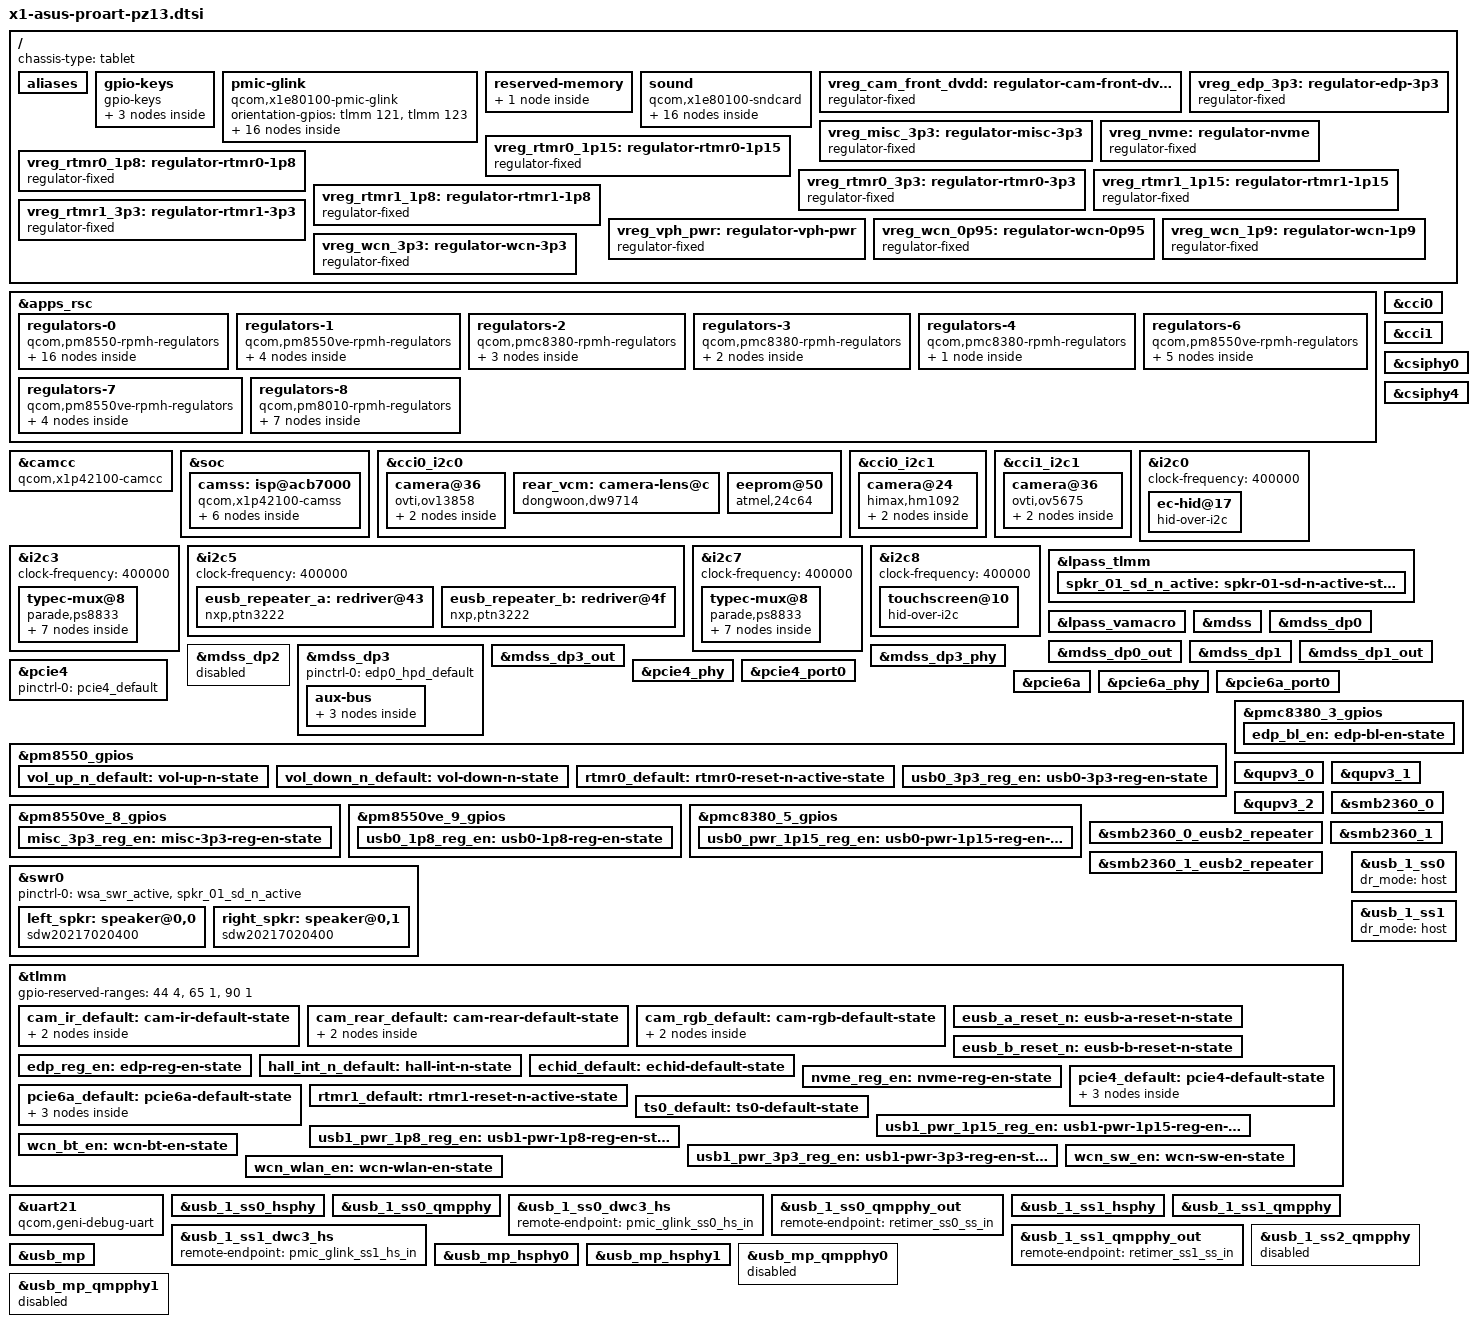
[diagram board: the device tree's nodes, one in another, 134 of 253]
// SPDX-License-Identifier: BSD-3-Clause
/*
 * Copyright (c) 2025 Qualcomm Innovation Center, Inc. All rights reserved.
 * Copyright (c) 2025 Aleksandrs Vinarskis <alex.vinarskis@gmail.com>
 * Copyright (c) 2026 Alex Grucza
 *
 * ASUS ProArt PZ13 (HT5306QA), Snapdragon X Plus X1P-42-100.
 * Derived from x1-asus-zenbook-a14.dtsi; bus assignments, interrupts and
 * supplies verified against the PZ13 ACPI DSDT and by probing. Remaining
 * open points carry a PZ13-TODO marker.
 */

#include <dt-bindings/gpio/gpio.h>
#include <dt-bindings/input/gpio-keys.h>
#include <dt-bindings/input/input.h>
#include <dt-bindings/phy/phy.h>
#include <dt-bindings/pinctrl/qcom,pmic-gpio.h>
#include <dt-bindings/regulator/qcom,rpmh-regulator.h>

#include "hamoa-pmics.dtsi"

/ {
	chassis-type = "tablet";

	aliases {
		serial0 = &uart21;
		serial1 = &uart14;
	};

	gpio-keys {
		compatible = "gpio-keys";

		pinctrl-0 = <&hall_int_n_default>, <&vol_up_n_default>, <&vol_down_n_default>;
		pinctrl-names = "default";

		switch-lid {
			label = "lid";
			gpios = <&tlmm 92 GPIO_ACTIVE_LOW>;
			linux,input-type = <EV_SW>;
			linux,code = <SW_LID>;
			wakeup-source;
			wakeup-event-action = <EV_ACT_DEASSERTED>;
		};

		/*
		 * ACPI \_SB.BTNS (ACPI0011): Volume Increment / Decrement on
		 * PMIC GPIO pins 0xd5 / 0xd7 of \_SB.PM01; pm8550 GPIO 6 and 8
		 * are the two lines the firmware leaves as inputs, as on the
		 * CRD (volume up on GPIO 6).
		 */
		key-vol-up {
			label = "volume_up";
			gpios = <&pm8550_gpios 6 GPIO_ACTIVE_LOW>;
			linux,code = <KEY_VOLUMEUP>;
			debounce-interval = <15>;
			linux,can-disable;
			wakeup-source;
		};

		key-vol-down {
			label = "volume_down";
			gpios = <&pm8550_gpios 8 GPIO_ACTIVE_LOW>;
			linux,code = <KEY_VOLUMEDOWN>;
			debounce-interval = <15>;
			linux,can-disable;
			wakeup-source;
		};
	};

	pmic-glink {
		compatible = "qcom,x1e80100-pmic-glink", "qcom,pmic-glink";
		orientation-gpios = <&tlmm 121 GPIO_ACTIVE_HIGH>,
				    <&tlmm 123 GPIO_ACTIVE_HIGH>;
		#address-cells = <1>;
		#size-cells = <0>;

		/* Left-side display-adjacent port */
		connector@0 {
			compatible = "usb-c-connector";
			reg = <0>;
			power-role = "dual";
			data-role = "dual";

			ports {
				#address-cells = <1>;
				#size-cells = <0>;

				port@0 {
					reg = <0>;

					pmic_glink_ss0_hs_in: endpoint {
						remote-endpoint = <&usb_1_ss0_dwc3_hs>;
					};
				};

				port@1 {
					reg = <1>;

					pmic_glink_ss0_ss_in: endpoint {
						remote-endpoint = <&retimer_ss0_ss_out>;
					};
				};

				port@2 {
					reg = <2>;

					pmic_glink_ss0_con_sbu_in: endpoint {
						remote-endpoint = <&retimer_ss0_con_sbu_out>;
					};
				};
			};
		};

		/* Left-side user-adjacent port */
		connector@1 {
			compatible = "usb-c-connector";
			reg = <1>;
			power-role = "dual";
			data-role = "dual";

			ports {
				#address-cells = <1>;
				#size-cells = <0>;

				port@0 {
					reg = <0>;

					pmic_glink_ss1_hs_in: endpoint {
						remote-endpoint = <&usb_1_ss1_dwc3_hs>;
					};
				};

				port@1 {
					reg = <1>;

					pmic_glink_ss1_ss_in: endpoint {
						remote-endpoint = <&retimer_ss1_ss_out>;
					};
				};

				port@2 {
					reg = <2>;

					pmic_glink_ss1_con_sbu_in: endpoint {
						remote-endpoint = <&retimer_ss1_con_sbu_out>;
					};
				};
			};
		};
	};

	reserved-memory {
		linux,cma {
			compatible = "shared-dma-pool";
			size = <0x0 0x8000000>;
			reusable;
			linux,cma-default;
		};
	};

	/*
	 * Audio, from the Windows audio driver INF (qcaudminiportCRD_Extension):
	 * stereo speakers on the Qualcomm smart-amp path (two WSA8845 on swr0,
	 * enumerated as sdw:1:0:0217:0204:00:{0,1}), a DMIC array on the VA
	 * macro, no headset jack and therefore no WCD codec (swr1/swr2 stay
	 * disabled; swr2 floods "SWR CMD error" interrupts if enabled).
	 * DisplayPort audio over the two USB-C ports as on the Zenbook A14.
	 */
	sound {
		compatible = "qcom,x1e80100-sndcard";
		model = "X1P42100-ASUS-ProArt-PZ13";
		/*
		 * No WCD codec here, so no "VA MIC BIASn" widgets: the DMICs are
		 * powered by the VA macro's vdd-micb-supply, which only gets
		 * enabled when routed to the DMIC inputs.
		 */
		audio-routing = "SpkrLeft IN", "WSA WSA_SPK1 OUT",
				"SpkrRight IN", "WSA WSA_SPK2 OUT",
				"VA DMIC0", "vdd-micb",
				"VA DMIC1", "vdd-micb",
				"VA DMIC2", "vdd-micb",
				"VA DMIC3", "vdd-micb";

		displayport-0-dai-link {
			link-name = "DisplayPort0 Playback";

			codec {
				sound-dai = <&mdss_dp0>;
			};

			cpu {
				sound-dai = <&q6apmbedai DISPLAY_PORT_RX_0>;
			};

			platform {
				sound-dai = <&q6apm>;
			};
		};

		displayport-1-dai-link {
			link-name = "DisplayPort1 Playback";

			codec {
				sound-dai = <&mdss_dp1>;
			};

			cpu {
				sound-dai = <&q6apmbedai DISPLAY_PORT_RX_1>;
			};

			platform {
				sound-dai = <&q6apm>;
			};
		};

		va-dai-link {
			link-name = "VA Capture";

			codec {
				sound-dai = <&lpass_vamacro 0>;
			};

			cpu {
				sound-dai = <&q6apmbedai VA_CODEC_DMA_TX_0>;
			};

			platform {
				sound-dai = <&q6apm>;
			};
		};

		wsa-dai-link {
			link-name = "WSA Playback";

			codec {
				sound-dai = <&left_spkr>, <&right_spkr>,
					    <&swr0 0>, <&lpass_wsamacro 0>;
			};

			cpu {
				sound-dai = <&q6apmbedai WSA_CODEC_DMA_RX_0>;
			};

			platform {
				sound-dai = <&q6apm>;
			};
		};
	};

	/*
	 * Front camera DVDD: the OV5675 module has no external 1.2 V rail in the
	 * Windows power sequence (notes/cameras.md), the sensor streams with AVDD and
	 * DOVDD alone, so the driver's required dvdd-supply is a dummy. (The TLMM 6
	 * toggle in that sequence is the eUSB2 repeater reset of usb_mp, not a camera
	 * supply.)
	 */
	vreg_cam_front_dvdd: regulator-cam-front-dvdd {
		compatible = "regulator-fixed";
		regulator-name = "vreg_cam_front_dvdd";
		regulator-min-microvolt = <1200000>;
		regulator-max-microvolt = <1200000>;
	};

	vreg_edp_3p3: regulator-edp-3p3 {
		compatible = "regulator-fixed";

		regulator-name = "VREG_EDP_3P3";
		regulator-min-microvolt = <3300000>;
		regulator-max-microvolt = <3300000>;

		gpio = <&tlmm 70 GPIO_ACTIVE_HIGH>;
		enable-active-high;

		pinctrl-0 = <&edp_reg_en>;
		pinctrl-names = "default";

		regulator-boot-on;
	};

	/*
	 * PZ13-TODO: inherited from the Zenbook A14, where it is boot-on with no
	 * DT consumer. Not referenced by the PZ13 PEP tables we have looked at;
	 * what pm8550ve_8 GPIO 6 switches on this board is unknown.
	 */
	vreg_misc_3p3: regulator-misc-3p3 {
		compatible = "regulator-fixed";

		regulator-name = "VREG_MISC_3P3";
		regulator-min-microvolt = <3300000>;
		regulator-max-microvolt = <3300000>;

		gpio = <&pm8550ve_8_gpios 6 GPIO_ACTIVE_HIGH>;
		enable-active-high;

		pinctrl-0 = <&misc_3p3_reg_en>;
		pinctrl-names = "default";

		regulator-boot-on;
		regulator-always-on;
	};

	vreg_nvme: regulator-nvme {
		compatible = "regulator-fixed";

		regulator-name = "VREG_NVME_3P3";
		regulator-min-microvolt = <3300000>;
		regulator-max-microvolt = <3300000>;

		gpio = <&tlmm 18 GPIO_ACTIVE_HIGH>;
		enable-active-high;

		pinctrl-0 = <&nvme_reg_en>;
		pinctrl-names = "default";

		regulator-boot-on;
	};

	vreg_rtmr0_1p15: regulator-rtmr0-1p15 {
		compatible = "regulator-fixed";

		regulator-name = "VREG_RTMR0_1P15";
		regulator-min-microvolt = <1150000>;
		regulator-max-microvolt = <1150000>;

		gpio = <&pmc8380_5_gpios 8 GPIO_ACTIVE_HIGH>;
		enable-active-high;

		pinctrl-0 = <&usb0_pwr_1p15_reg_en>;
		pinctrl-names = "default";

		regulator-boot-on;
	};

	vreg_rtmr0_1p8: regulator-rtmr0-1p8 {
		compatible = "regulator-fixed";

		regulator-name = "VREG_RTMR0_1P8";
		regulator-min-microvolt = <1800000>;
		regulator-max-microvolt = <1800000>;

		gpio = <&pm8550ve_9_gpios 8 GPIO_ACTIVE_HIGH>;
		enable-active-high;

		pinctrl-0 = <&usb0_1p8_reg_en>;
		pinctrl-names = "default";

		regulator-boot-on;
	};

	vreg_rtmr0_3p3: regulator-rtmr0-3p3 {
		compatible = "regulator-fixed";

		regulator-name = "VREG_RTMR0_3P3";
		regulator-min-microvolt = <3300000>;
		regulator-max-microvolt = <3300000>;

		gpio = <&pm8550_gpios 11 GPIO_ACTIVE_HIGH>;
		enable-active-high;

		pinctrl-0 = <&usb0_3p3_reg_en>;
		pinctrl-names = "default";

		regulator-boot-on;
	};

	vreg_rtmr1_1p15: regulator-rtmr1-1p15 {
		compatible = "regulator-fixed";

		regulator-name = "VREG_RTMR1_1P15";
		regulator-min-microvolt = <1150000>;
		regulator-max-microvolt = <1150000>;

		gpio = <&tlmm 188 GPIO_ACTIVE_HIGH>;
		enable-active-high;

		pinctrl-0 = <&usb1_pwr_1p15_reg_en>;
		pinctrl-names = "default";

		regulator-boot-on;
	};

	vreg_rtmr1_1p8: regulator-rtmr1-1p8 {
		compatible = "regulator-fixed";

		regulator-name = "VREG_RTMR1_1P8";
		regulator-min-microvolt = <1800000>;
		regulator-max-microvolt = <1800000>;

		gpio = <&tlmm 175 GPIO_ACTIVE_HIGH>;
		enable-active-high;

		pinctrl-0 = <&usb1_pwr_1p8_reg_en>;
		pinctrl-names = "default";

		regulator-boot-on;
	};

	vreg_rtmr1_3p3: regulator-rtmr1-3p3 {
		compatible = "regulator-fixed";

		regulator-name = "VREG_RTMR1_3P3";
		regulator-min-microvolt = <3300000>;
		regulator-max-microvolt = <3300000>;

		gpio = <&tlmm 186 GPIO_ACTIVE_HIGH>;
		enable-active-high;

		pinctrl-0 = <&usb1_pwr_3p3_reg_en>;
		pinctrl-names = "default";

		regulator-boot-on;
	};

	vreg_vph_pwr: regulator-vph-pwr {
		compatible = "regulator-fixed";

		regulator-name = "vph_pwr";
		regulator-min-microvolt = <3700000>;
		regulator-max-microvolt = <3700000>;

		regulator-always-on;
		regulator-boot-on;
	};

	vreg_wcn_0p95: regulator-wcn-0p95 {
		compatible = "regulator-fixed";

		regulator-name = "VREG_WCN_0P95";
		regulator-min-microvolt = <950000>;
		regulator-max-microvolt = <950000>;

		vin-supply = <&vreg_wcn_3p3>;
	};

	vreg_wcn_1p9: regulator-wcn-1p9 {
		compatible = "regulator-fixed";

		regulator-name = "VREG_WCN_1P9";
		regulator-min-microvolt = <1900000>;
		regulator-max-microvolt = <1900000>;

		vin-supply = <&vreg_wcn_3p3>;
	};

	vreg_wcn_3p3: regulator-wcn-3p3 {
		compatible = "regulator-fixed";

		regulator-name = "VREG_WCN_3P3";
		regulator-min-microvolt = <3300000>;
		regulator-max-microvolt = <3300000>;

		gpio = <&tlmm 214 GPIO_ACTIVE_HIGH>;
		enable-active-high;

		pinctrl-0 = <&wcn_sw_en>;
		pinctrl-names = "default";

		regulator-boot-on;
	};
};

&apps_rsc {
	regulators-0 {
		compatible = "qcom,pm8550-rpmh-regulators";
		qcom,pmic-id = "b";

		vdd-bob1-supply = <&vreg_vph_pwr>;
		vdd-bob2-supply = <&vreg_vph_pwr>;
		vdd-l1-l4-l10-supply = <&vreg_s4c_1p8>;
		vdd-l2-l13-l14-supply = <&vreg_bob1>;
		vdd-l5-l16-supply = <&vreg_bob1>;
		vdd-l6-l7-supply = <&vreg_bob2>;
		vdd-l8-l9-supply = <&vreg_bob1>;
		vdd-l12-supply = <&vreg_s5j_1p2>;
		vdd-l15-supply = <&vreg_s4c_1p8>;
		vdd-l17-supply = <&vreg_bob2>;

		vreg_bob1: bob1 {
			regulator-name = "vreg_bob1";
			regulator-min-microvolt = <3008000>;
			regulator-max-microvolt = <3960000>;
			regulator-initial-mode = <RPMH_REGULATOR_MODE_HPM>;
		};

		vreg_bob2: bob2 {
			regulator-name = "vreg_bob2";
			regulator-min-microvolt = <2504000>;
			regulator-max-microvolt = <3008000>;
			regulator-initial-mode = <RPMH_REGULATOR_MODE_HPM>;
		};

		vreg_l1b_1p8: ldo1 {
			regulator-name = "vreg_l1b_1p8";
			regulator-min-microvolt = <1800000>;
			regulator-max-microvolt = <1800000>;
			regulator-initial-mode = <RPMH_REGULATOR_MODE_HPM>;
		};

		vreg_l2b_3p0: ldo2 {
			regulator-name = "vreg_l2b_3p0";
			regulator-min-microvolt = <3072000>;
			regulator-max-microvolt = <3072000>;
			regulator-initial-mode = <RPMH_REGULATOR_MODE_HPM>;
		};

		vreg_l4b_1p8: ldo4 {
			regulator-name = "vreg_l4b_1p8";
			regulator-min-microvolt = <1800000>;
			regulator-max-microvolt = <1800000>;
			regulator-initial-mode = <RPMH_REGULATOR_MODE_HPM>;
		};

		vreg_l5b_3p0: ldo5 {
			regulator-name = "vreg_l5b_3p0";
			regulator-min-microvolt = <3000000>;
			regulator-max-microvolt = <3000000>;
			regulator-initial-mode = <RPMH_REGULATOR_MODE_HPM>;
		};

		vreg_l7b_2p8: ldo7 {
			regulator-name = "vreg_l7b_2p8";
			regulator-min-microvolt = <2800000>;
			regulator-max-microvolt = <2800000>;
			regulator-initial-mode = <RPMH_REGULATOR_MODE_HPM>;
		};

		vreg_l6b_1p8: ldo6 {
			regulator-name = "vreg_l6b_1p8";
			regulator-min-microvolt = <1800000>;
			regulator-max-microvolt = <2960000>;
			regulator-initial-mode = <RPMH_REGULATOR_MODE_HPM>;
		};

		vreg_l8b_3p0: ldo8 {
			regulator-name = "vreg_l8b_3p0";
			regulator-min-microvolt = <3072000>;
			regulator-max-microvolt = <3072000>;
			regulator-initial-mode = <RPMH_REGULATOR_MODE_HPM>;
		};

		vreg_l9b_2p9: ldo9 {
			regulator-name = "vreg_l9b_2p9";
			regulator-min-microvolt = <2960000>;
			regulator-max-microvolt = <2960000>;
			regulator-initial-mode = <RPMH_REGULATOR_MODE_HPM>;
		};

		vreg_l10b_1p8: ldo10 {
			regulator-name = "vreg_l10b_1p8";
			regulator-min-microvolt = <1800000>;
			regulator-max-microvolt = <1800000>;
			regulator-initial-mode = <RPMH_REGULATOR_MODE_HPM>;
		};

		vreg_l12b_1p2: ldo12 {
			regulator-name = "vreg_l12b_1p2";
			regulator-min-microvolt = <1200000>;
			regulator-max-microvolt = <1200000>;
			regulator-initial-mode = <RPMH_REGULATOR_MODE_HPM>;
			regulator-always-on;
		};

		vreg_l13b_3p0: ldo13 {
			regulator-name = "vreg_l13b_3p0";
			regulator-min-microvolt = <3072000>;
			regulator-max-microvolt = <3072000>;
			regulator-initial-mode = <RPMH_REGULATOR_MODE_HPM>;
		};

		vreg_l14b_3p0: ldo14 {
			regulator-name = "vreg_l14b_3p0";
			regulator-min-microvolt = <3072000>;
			regulator-max-microvolt = <3072000>;
			regulator-initial-mode = <RPMH_REGULATOR_MODE_HPM>;
		};

		vreg_l15b_1p8: ldo15 {
			regulator-name = "vreg_l15b_1p8";
			regulator-min-microvolt = <1800000>;
			regulator-max-microvolt = <1800000>;
			regulator-initial-mode = <RPMH_REGULATOR_MODE_HPM>;
			regulator-always-on;
		};

		vreg_l17b_2p5: ldo17 {
			regulator-name = "vreg_l17b_2p5";
			regulator-min-microvolt = <2504000>;
			regulator-max-microvolt = <2504000>;
			regulator-initial-mode = <RPMH_REGULATOR_MODE_HPM>;
		};
	};

	regulators-1 {
		compatible = "qcom,pm8550ve-rpmh-regulators";
		qcom,pmic-id = "c";

		vdd-l1-supply = <&vreg_s5j_1p2>;
		vdd-l2-supply = <&vreg_s1f_0p7>;
		vdd-l3-supply = <&vreg_s1f_0p7>;
		vdd-s4-supply = <&vreg_vph_pwr>;

		vreg_s4c_1p8: smps4 {
			regulator-name = "vreg_s4c_1p8";
			regulator-min-microvolt = <1856000>;
			regulator-max-microvolt = <2000000>;
			regulator-initial-mode = <RPMH_REGULATOR_MODE_HPM>;
		};

		vreg_l1c_1p2: ldo1 {
			regulator-name = "vreg_l1c_1p2";
			regulator-min-microvolt = <1200000>;
			regulator-max-microvolt = <1200000>;
			regulator-initial-mode = <RPMH_REGULATOR_MODE_HPM>;
		};

		vreg_l2c_0p8: ldo2 {
			regulator-name = "vreg_l2c_0p8";
			regulator-min-microvolt = <880000>;
			regulator-max-microvolt = <880000>;
			regulator-initial-mode = <RPMH_REGULATOR_MODE_HPM>;
		};

		vreg_l3c_0p9: ldo3 {
			regulator-name = "vreg_l3c_0p9";
			regulator-min-microvolt = <912000>;
			regulator-max-microvolt = <912000>;
			regulator-initial-mode = <RPMH_REGULATOR_MODE_HPM>;
		};
	};

	regulators-2 {
		compatible = "qcom,pmc8380-rpmh-regulators";
		qcom,pmic-id = "d";

		vdd-l1-supply = <&vreg_s1f_0p7>;
		vdd-l2-supply = <&vreg_s1f_0p7>;
		vdd-l3-supply = <&vreg_s4c_1p8>;
		vdd-s1-supply = <&vreg_vph_pwr>;

		vreg_l1d_0p8: ldo1 {
			regulator-name = "vreg_l1d_0p8";
			regulator-min-microvolt = <880000>;
			regulator-max-microvolt = <880000>;
			regulator-initial-mode = <RPMH_REGULATOR_MODE_HPM>;
		};

		vreg_l2d_0p9: ldo2 {
			regulator-name = "vreg_l2d_0p9";
			regulator-min-microvolt = <912000>;
			regulator-max-microvolt = <912000>;
			regulator-initial-mode = <RPMH_REGULATOR_MODE_HPM>;
		};

		vreg_l3d_1p8: ldo3 {
			regulator-name = "vreg_l3d_1p8";
			regulator-min-microvolt = <1800000>;
			regulator-max-microvolt = <1800000>;
			regulator-initial-mode = <RPMH_REGULATOR_MODE_HPM>;
		};
	};

	regulators-3 {
		compatible = "qcom,pmc8380-rpmh-regulators";
		qcom,pmic-id = "e";

		vdd-l2-supply = <&vreg_s1f_0p7>;
		vdd-l3-supply = <&vreg_s5j_1p2>;

		vreg_l2e_0p8: ldo2 {
			regulator-name = "vreg_l2e_0p8";
			regulator-min-microvolt = <880000>;
			regulator-max-microvolt = <880000>;
			regulator-initial-mode = <RPMH_REGULATOR_MODE_HPM>;
		};

		vreg_l3e_1p2: ldo3 {
			regulator-name = "vreg_l3e_1p2";
			regulator-min-microvolt = <1200000>;
			regulator-max-microvolt = <1200000>;
			regulator-initial-mode = <RPMH_REGULATOR_MODE_HPM>;
		};
	};

	regulators-4 {
		compatible = "qcom,pmc8380-rpmh-regulators";
		qcom,pmic-id = "f";

		vdd-l1-supply = <&vreg_s5j_1p2>;
		vdd-l2-supply = <&vreg_s5j_1p2>;
		vdd-l3-supply = <&vreg_s5j_1p2>;
		vdd-s1-supply = <&vreg_vph_pwr>;

		vreg_s1f_0p7: smps1 {
			regulator-name = "vreg_s1f_0p7";
			regulator-min-microvolt = <700000>;
			regulator-max-microvolt = <1100000>;
			regulator-initial-mode = <RPMH_REGULATOR_MODE_HPM>;
		};
	};

	regulators-6 {
		compatible = "qcom,pm8550ve-rpmh-regulators";
		qcom,pmic-id = "i";

		vdd-l1-supply = <&vreg_s4c_1p8>;
		vdd-l2-supply = <&vreg_s5j_1p2>;
		vdd-l3-supply = <&vreg_s1f_0p7>;
		vdd-s1-supply = <&vreg_vph_pwr>;
		vdd-s2-supply = <&vreg_vph_pwr>;

		vreg_s1i_0p9: smps1 {
			regulator-name = "vreg_s1i_0p9";
			regulator-min-microvolt = <900000>;
			regulator-max-microvolt = <920000>;
			regulator-initial-mode = <RPMH_REGULATOR_MODE_HPM>;
		};

		vreg_s2i_1p0: smps2 {
			regulator-name = "vreg_s2i_1p0";
			regulator-min-microvolt = <1000000>;
			regulator-max-microvolt = <1100000>;
			regulator-initial-mode = <RPMH_REGULATOR_MODE_HPM>;
		};

		vreg_l1i_1p8: ldo1 {
			regulator-name = "vreg_l1i_1p8";
			regulator-min-microvolt = <1800000>;
			regulator-max-microvolt = <1800000>;
			regulator-initial-mode = <RPMH_REGULATOR_MODE_HPM>;
		};

		vreg_l2i_1p2: ldo2 {
			regulator-name = "vreg_l2i_1p2";
			regulator-min-microvolt = <1200000>;
			regulator-max-microvolt = <1200000>;
			regulator-initial-mode = <RPMH_REGULATOR_MODE_HPM>;
		};

		vreg_l3i_0p8: ldo3 {
			regulator-name = "vreg_l3i_0p8";
			regulator-min-microvolt = <880000>;
			regulator-max-microvolt = <880000>;
			regulator-initial-mode = <RPMH_REGULATOR_MODE_HPM>;
		};
	};

	regulators-7 {
		compatible = "qcom,pm8550ve-rpmh-regulators";
		qcom,pmic-id = "j";

		vdd-l1-supply = <&vreg_s1f_0p7>;
		vdd-l2-supply = <&vreg_s5j_1p2>;
		vdd-l3-supply = <&vreg_s1f_0p7>;
		vdd-s5-supply = <&vreg_vph_pwr>;

		vreg_s5j_1p2: smps5 {
			regulator-name = "vreg_s5j_1p2";
			regulator-min-microvolt = <1256000>;
			regulator-max-microvolt = <1304000>;
			regulator-initial-mode = <RPMH_REGULATOR_MODE_HPM>;
		};

		vreg_l1j_0p9: ldo1 {
			regulator-name = "vreg_l1j_0p9";
			regulator-min-microvolt = <912000>;
			regulator-max-microvolt = <912000>;
			regulator-initial-mode = <RPMH_REGULATOR_MODE_HPM>;
		};

		vreg_l2j_1p2: ldo2 {
			regulator-name = "vreg_l2j_1p2";
			regulator-min-microvolt = <1256000>;
			regulator-max-microvolt = <1256000>;
			regulator-initial-mode = <RPMH_REGULATOR_MODE_HPM>;
		};

		vreg_l3j_0p8: ldo3 {
			regulator-name = "vreg_l3j_0p8";
			regulator-min-microvolt = <880000>;
			regulator-max-microvolt = <880000>;
			regulator-initial-mode = <RPMH_REGULATOR_MODE_HPM>;
			/*
			 * PZ13: supplies the QREF block that generates the
			 * reference clocks for the PCIe/USB QMP PHYs (Windows
			 * votes LDO3_J for every PCIe port). Until the TCSR
			 * clk_ref/QREF series describes this properly, keep
			 * it on so the PHYs never init before it is up.
			 */
			regulator-always-on;
			regulator-boot-on;
		};
	};
	/*
	 * PM8010 (camera PMIC, pmic-id "m"). All seven LDOs exist in cmd-db
	 * (ldom1..ldom7). Voltages from the Windows camera power sequences, supply
	 * parents as on the X1E CRD. l5m (2.8 V) feeds the rear camera's VCM.
	 */
	regulators-8 {
		compatible = "qcom,pm8010-rpmh-regulators";
		qcom,pmic-id = "m";

		vdd-l1-l2-supply = <&vreg_s5j_1p2>;
		vdd-l3-l4-supply = <&vreg_s4c_1p8>;
		vdd-l5-supply = <&vreg_bob1>;
		vdd-l6-supply = <&vreg_s4c_1p8>;
		vdd-l7-supply = <&vreg_bob1>;

		vreg_l1m_1p2: ldo1 {
			regulator-name = "vreg_l1m_1p2";
			regulator-min-microvolt = <1200000>;
			regulator-max-microvolt = <1200000>;
			regulator-initial-mode = <RPMH_REGULATOR_MODE_HPM>;
		};

		vreg_l2m_1p2: ldo2 {
			regulator-name = "vreg_l2m_1p2";
			regulator-min-microvolt = <1200000>;
			regulator-max-microvolt = <1200000>;
			regulator-initial-mode = <RPMH_REGULATOR_MODE_HPM>;
		};

		vreg_l3m_1p8: ldo3 {
			regulator-name = "vreg_l3m_1p8";
			regulator-min-microvolt = <1800000>;
			regulator-max-microvolt = <1808000>;
			regulator-initial-mode = <RPMH_REGULATOR_MODE_HPM>;
		};

		/*
		 * I/O rail of the IR camera (its dovdd-supply). The rear camera's
		 * sensor only answers on cci0_i2c0 while this rail is on as well
		 * (Windows switches it on in the rear camera's sequence too),
		 * presumably the pull-ups of that bus hang on it. Nothing can
		 * request it on behalf of a bus, so keep it on (PZ13-TODO).
		 */
		vreg_l4m_1p8: ldo4 {
			regulator-name = "vreg_l4m_1p8";
			regulator-min-microvolt = <1800000>;
			regulator-max-microvolt = <1808000>;
			regulator-initial-mode = <RPMH_REGULATOR_MODE_HPM>;
			regulator-always-on;
		};

		vreg_l5m_2p8: ldo5 {
			regulator-name = "vreg_l5m_2p8";
			regulator-min-microvolt = <2800000>;
			regulator-max-microvolt = <2800000>;
			regulator-initial-mode = <RPMH_REGULATOR_MODE_HPM>;
		};

		vreg_l6m_1p8: ldo6 {
			regulator-name = "vreg_l6m_1p8";
			regulator-min-microvolt = <1800000>;
			regulator-max-microvolt = <1808000>;
			regulator-initial-mode = <RPMH_REGULATOR_MODE_HPM>;
		};

		vreg_l7m_2p8: ldo7 {
			regulator-name = "vreg_l7m_2p8";
			regulator-min-microvolt = <2800000>;
			regulator-max-microvolt = <2800000>;
			regulator-initial-mode = <RPMH_REGULATOR_MODE_HPM>;
		};
	};

};

/*
 * Cameras. Wiring decoded from the Windows camera package (notes/cameras.md):
 * the PZ13 follows the Qualcomm CRD/QRD reference layout. Front RGB OV5675 on
 * cci1_i2c1 / csiphy4 / MCLK4 works (libcamera). IR HM1092 on
 * cci0_i2c1 / MCLK1 / reset tlmm 111 shares csiphy4 with the RGB sensor in
 * Qualcomm "combo mode": RGB on DL0/DL1 with the clock lane, IR on DL2 with
 * DL3 as its clock lane (module descriptions: isComboMode = 1, laneAssign 2).
 * Streams with the camss/csiphy combo-mode patches in patches/.
 * Rear OV13858 on cci0_i2c0 / csiphy0 (4 lanes) / MCLK0, reset tlmm 109;
 * needs the ov13858 device-tree support patch in patches/; VCM dw9714 @0x0c
 * and module EEPROM 24c64 @0x50 on the same bus.
 * PZ13-TODO: PM8550 IR illuminator (\_SB.FLSH in ACPI).
 */
/*
 * X1P42100 (Purwa) has a smaller CAMSS than the X1E80100 described in
 * hamoa.dtsi: no IFE1, no SFE, CSIPHY0 and CSIPHY4 only. With the X1E
 * description the kernel toggles the non-existent IFE1 GDSC on every suspend
 * and resume ("cam_cc_ife_1_gdsc status stuck"). Redefine the node per the
 * qcom,x1p42100-camss binding (Wenmeng Liu, linux-media, v3; patches/) until purwa.dtsi carries it. Ports: port@0 => csiphy0,
 * port@1 => csiphy4.
 */
&camcc {
	compatible = "qcom,x1p42100-camcc";
};

/*
 * The X1E80100 CAMSS node from hamoa.dtsi is replaced by an X1P42100 one
 * (different unit address, register set and power domains), see below.
 */
/delete-node/ &camss;

&soc {
	camss: isp@acb7000 {
		compatible = "qcom,x1p42100-camss";
		reg = <0 0x0acb7000 0 0x2000>,
		      <0 0x0acb9000 0 0x2000>,
		      <0 0x0acbb000 0 0x2000>,
		      <0 0x0acc6000 0 0x1000>,
		      <0 0x0acca000 0 0x1000>,
		      <0 0x0acb6000 0 0x1000>,
		      <0 0x0acf6000 0 0x1000>,
		      <0 0x0acf7000 0 0x1000>,
		      <0 0x0acf8000 0 0x1000>,
		      <0 0x0ac62000 0 0xf000>,
		      <0 0x0acc7000 0 0x1000>,
		      <0 0x0accb000 0 0x1000>;
		reg-names = "csid0",
			    "csid1",
			    "csid2",
			    "csid_lite0",
			    "csid_lite1",
			    "csid_wrapper",
			    "csitpg0",
			    "csitpg1",
			    "csitpg2",
			    "vfe0",
			    "vfe_lite0",
			    "vfe_lite1";
		clocks = <&camcc CAM_CC_CAMNOC_AXI_RT_CLK>,
			 <&camcc CAM_CC_CPAS_AHB_CLK>,
			 <&camcc CAM_CC_CPAS_FAST_AHB_CLK>,
			 <&camcc CAM_CC_CPAS_IFE_0_CLK>,
			 <&camcc CAM_CC_CPAS_IFE_LITE_CLK>,
			 <&camcc CAM_CC_CSID_CLK>,
			 <&camcc CAM_CC_CSID_CSIPHY_RX_CLK>,
			 <&gcc GCC_CAMERA_HF_AXI_CLK>,
			 <&camcc CAM_CC_IFE_0_CLK>,
			 <&camcc CAM_CC_IFE_0_FAST_AHB_CLK>,
			 <&camcc CAM_CC_IFE_LITE_CLK>,
			 <&camcc CAM_CC_IFE_LITE_AHB_CLK>,
			 <&camcc CAM_CC_IFE_LITE_CPHY_RX_CLK>,
			 <&camcc CAM_CC_IFE_LITE_CSID_CLK>;
		clock-names = "camnoc_rt_axi",
			      "cpas_ahb",
			      "cpas_fast_ahb",
			      "cpas_vfe0",
			      "cpas_vfe_lite",
			      "csid",
			      "csid_csiphy_rx",
			      "gcc_axi_hf",
			      "vfe0",
			      "vfe0_fast_ahb",
			      "vfe_lite",
			      "vfe_lite_ahb",
			      "vfe_lite_cphy_rx",
			      "vfe_lite_csid";
		interrupts = <GIC_SPI 464 IRQ_TYPE_EDGE_RISING>,
			     <GIC_SPI 466 IRQ_TYPE_EDGE_RISING>,
			     <GIC_SPI 431 IRQ_TYPE_EDGE_RISING>,
			     <GIC_SPI 468 IRQ_TYPE_EDGE_RISING>,
			     <GIC_SPI 359 IRQ_TYPE_EDGE_RISING>,
			     <GIC_SPI 465 IRQ_TYPE_EDGE_RISING>,
			     <GIC_SPI 469 IRQ_TYPE_EDGE_RISING>,
			     <GIC_SPI 360 IRQ_TYPE_EDGE_RISING>;
		interrupt-names = "csid0",
				  "csid1",
				  "csid2",
				  "csid_lite0",
				  "csid_lite1",
				  "vfe0",
				  "vfe_lite0",
				  "vfe_lite1";
		interconnects = <&gem_noc MASTER_APPSS_PROC QCOM_ICC_TAG_ACTIVE_ONLY
				 &config_noc SLAVE_CAMERA_CFG QCOM_ICC_TAG_ACTIVE_ONLY>,
				<&mmss_noc MASTER_CAMNOC_HF QCOM_ICC_TAG_ALWAYS
				 &mc_virt SLAVE_EBI1 QCOM_ICC_TAG_ALWAYS>;
		interconnect-names = "ahb",
				     "hf_mnoc";
		iommus = <&apps_smmu 0x800 0x60>,
			 <&apps_smmu 0x820 0x60>;
		phys = <&csiphy0>, <&csiphy4>;
		phy-names = "csiphy0", "csiphy4";
		power-domains = <&camcc CAM_CC_IFE_0_GDSC>,
				<&camcc CAM_CC_TITAN_TOP_GDSC>;
		power-domain-names = "ife0",
				     "top";

		status = "okay";

		ports {
			#address-cells = <1>;
			#size-cells = <0>;

			/* port0 => csiphy0, port1 => csiphy4 */
			port@0 {
				reg = <0>;
				#address-cells = <1>;
				#size-cells = <0>;

				csiphy0_ep: endpoint@0 {
					reg = <0>;
					clock-lanes = <7>;
					data-lanes = <0 1 2 3>;
					remote-endpoint = <&ov13858_ep>;
				};
			};

			port@1 {
				reg = <1>;
				#address-cells = <1>;
				#size-cells = <0>;

				csiphy4_ep: endpoint@4 {
					reg = <4>;
					clock-lanes = <7>;
					data-lanes = <0 1>;
					remote-endpoint = <&ov5675_ep>;
				};

				csiphy4_ir_ep: endpoint@5 {
					reg = <5>;
					clock-lanes = <7>;
					data-lanes = <2>;
					remote-endpoint = <&hm1092_ep>;
				};
			};
		};
	};
};

&cci0 {
	status = "okay";
};

&cci0_i2c0 {
	/* Rear (world-facing) camera; the module straps the sensor to 0x36 */
	camera@36 {
		compatible = "ovti,ov13858";
		reg = <0x36>;

		reset-gpios = <&tlmm 109 GPIO_ACTIVE_LOW>;
		pinctrl-0 = <&cam_rear_default>;
		pinctrl-names = "default";

		/* Windows runs MCLK0 at 24 MHz; the Linux driver requires 19.2 MHz */
		clocks = <&camcc CAM_CC_MCLK0_CLK>;
		assigned-clocks = <&camcc CAM_CC_MCLK0_CLK>;
		assigned-clock-rates = <19200000>;

		orientation = <1>;

		avdd-supply = <&vreg_l7b_2p8>;
		dovdd-supply = <&vreg_l6m_1p8>;
		dvdd-supply = <&vreg_l2m_1p2>;

		lens-focus = <&rear_vcm>;

		port {
			ov13858_ep: endpoint {
				data-lanes = <1 2 3 4>;
				link-frequencies = /bits/ 64 <540000000 270000000>;
				remote-endpoint = <&csiphy0_ep>;
			};
		};
	};

	/* Rear camera focus motor (Windows module data: actuator at 0x18 8-bit) */
	rear_vcm: camera-lens@c {
		compatible = "dongwoon,dw9714";
		reg = <0x0c>;
		vcc-supply = <&vreg_l5m_2p8>;
	};

	/* Rear camera module EEPROM (Windows module data: 0xa0 8-bit, 16-bit addresses) */
	eeprom@50 {
		compatible = "atmel,24c64";
		reg = <0x50>;
		vcc-supply = <&vreg_l6m_1p8>;
		read-only;
	};
};

&cci0_i2c1 {
	/* Front IR camera (Windows Hello) */
	camera@24 {
		compatible = "himax,hm1092";
		reg = <0x24>;

		reset-gpios = <&tlmm 111 GPIO_ACTIVE_LOW>;
		pinctrl-0 = <&cam_ir_default>;
		pinctrl-names = "default";

		clocks = <&camcc CAM_CC_MCLK1_CLK>;
		assigned-clocks = <&camcc CAM_CC_MCLK1_CLK>;
		assigned-clock-rates = <24000000>;

		orientation = <0>;
		rotation = <180>;

		avdd-supply = <&vreg_l7m_2p8>;
		dvdd-supply = <&vreg_l1m_1p2>;
		dovdd-supply = <&vreg_l4m_1p8>;

		port {
			hm1092_ep: endpoint {
				data-lanes = <1>;
				link-frequencies = /bits/ 64 <180000000>;
				remote-endpoint = <&csiphy4_ir_ep>;
			};
		};
	};
};

&cci1 {
	status = "okay";
};

&cci1_i2c1 {
	/* Front (user-facing) camera */
	camera@36 {
		compatible = "ovti,ov5675";
		reg = <0x36>;

		reset-gpios = <&tlmm 237 GPIO_ACTIVE_LOW>;
		pinctrl-0 = <&cam_rgb_default>;
		pinctrl-names = "default";

		/* Windows runs MCLK4 at 24 MHz; the Linux driver requires 19.2 MHz */
		clocks = <&camcc CAM_CC_MCLK4_CLK>;
		assigned-clocks = <&camcc CAM_CC_MCLK4_CLK>;
		assigned-clock-rates = <19200000>;

		orientation = <0>;

		avdd-supply = <&vreg_l5b_3p0>;
		dovdd-supply = <&vreg_l3m_1p8>;
		dvdd-supply = <&vreg_cam_front_dvdd>;

		port {
			ov5675_ep: endpoint {
				data-lanes = <1 2>;
				link-frequencies = /bits/ 64 <450000000>;
				remote-endpoint = <&csiphy4_ep>;
			};
		};
	};
};

&csiphy0 {
	vdda-0p8-supply = <&vreg_l2c_0p8>;
	vdda-1p2-supply = <&vreg_l1c_1p2>;
	phy-type = <PHY_TYPE_DPHY>;

	status = "okay";
};

&csiphy4 {
	vdda-0p8-supply = <&vreg_l2c_0p8>;
	vdda-1p2-supply = <&vreg_l1c_1p2>;
	phy-type = <PHY_TYPE_DPHY>;

	status = "okay";
};

&i2c0 {
	/* ACPI: \_SB.I2C1 = QUP_0_SE_0 @ 0x00b80000 = Linux i2c0, 400 kHz */
	clock-frequency = <400000>;

	status = "okay";

	/*
	 * ACPI: \_SB.ECKB, _HID QTEC0001, _CID PNP0C50, _UID 3, slave 0x17,
	 * HID descriptor register 0x0001, GpioInt edge-low shared.
	 * This is the ASUS EC HID channel (hotkeys, tablet mode), the same
	 * kind of device the Zenbook A14 exposes as hdtl@17 (0B05:4543).
	 * The detachable keyboard cover is a plain USB device (0B05:1B6E)
	 * and needs nothing here.
	 * Interrupt on tlmm 67 (ACPI handle 0x0180 is a PEP handle, not a TLMM
	 * number); the device binds and answers, whether the IRQ fires on
	 * hotkeys is still unverified (PZ13-TODO).
	 */
	ec-hid@17 {
		compatible = "hid-over-i2c";
		reg = <0x17>;

		hid-descr-addr = <0x1>;
		interrupts-extended = <&tlmm 67 IRQ_TYPE_LEVEL_LOW>;

		pinctrl-0 = <&echid_default>;
		pinctrl-names = "default";

		wakeup-source;
	};
};

&i2c3 {
	clock-frequency = <400000>;

	status = "okay";

	/* Left-side display-adjacent port */
	typec-mux@8 {
		compatible = "parade,ps8833", "parade,ps8830";
		reg = <0x08>;

		clocks = <&rpmhcc RPMH_RF_CLK3>;

		vdd-supply = <&vreg_rtmr0_1p15>;
		vdd33-supply = <&vreg_rtmr0_3p3>;
		vdd33-cap-supply = <&vreg_rtmr0_3p3>;
		vddar-supply = <&vreg_rtmr0_1p15>;
		vddat-supply = <&vreg_rtmr0_1p15>;
		vddio-supply = <&vreg_rtmr0_1p8>;

		reset-gpios = <&pm8550_gpios 10 GPIO_ACTIVE_LOW>;

		pinctrl-0 = <&rtmr0_default>;
		pinctrl-names = "default";

		retimer-switch;
		orientation-switch;

		ports {
			#address-cells = <1>;
			#size-cells = <0>;

			port@0 {
				reg = <0>;

				retimer_ss0_ss_out: endpoint {
					remote-endpoint = <&pmic_glink_ss0_ss_in>;
				};
			};

			port@1 {
				reg = <1>;

				retimer_ss0_ss_in: endpoint {
					remote-endpoint = <&usb_1_ss0_qmpphy_out>;
				};
			};

			port@2 {
				reg = <2>;

				retimer_ss0_con_sbu_out: endpoint {
					remote-endpoint = <&pmic_glink_ss0_con_sbu_in>;
				};
			};
		};
	};
};

/*
 * ACPI: \_SB.I2C6 = QUP_0_SE_5 @ 0x00b94000 = Linux i2c5. This is the ASUS EC
 * bus (EC @0x5b, second device @0x76, both answer on i2cdetect). The Zenbook's
 * PTN3222 eUSB repeater @0x4f is not present here (not in ACPI, usb_mp port 1
 * is unconnected on the PZ13).
 * PZ13-TODO: EC driver (protocol documented in README.md).
 */
/*
 * ACPI: \_SB.USB3 (QCOM0D08, the multiport host at 0x0a400000) lists two I2C
 * devices on \_SB.I2C6 (= i2c5) at 0x43 and 0x4f and GpioIo 6 and 184: the two
 * eUSB2 repeaters of usb_mp with their reset lines, as on the other X1 laptops
 * (nxp,ptn3222). They probe. The cover's behaviour across suspend is governed
 * by the missing USB wakeup (see &usb_mp), not by the repeaters. Which repeater
 * serves which port follows the Zenbook A14 (0x4f/tlmm 184 on hsphy1 = cover);
 * PZ13-TODO: confirm.
 */
&i2c5 {
	clock-frequency = <400000>;

	status = "okay";

	eusb_repeater_a: redriver@43 {
		compatible = "nxp,ptn3222";
		reg = <0x43>;
		#phy-cells = <0>;

		vdd3v3-supply = <&vreg_l13b_3p0>;
		vdd1v8-supply = <&vreg_l4b_1p8>;

		reset-gpios = <&tlmm 6 GPIO_ACTIVE_LOW>;

		pinctrl-0 = <&eusb_a_reset_n>;
		pinctrl-names = "default";
	};

	eusb_repeater_b: redriver@4f {
		compatible = "nxp,ptn3222";
		reg = <0x4f>;
		#phy-cells = <0>;

		vdd3v3-supply = <&vreg_l13b_3p0>;
		vdd1v8-supply = <&vreg_l4b_1p8>;

		reset-gpios = <&tlmm 184 GPIO_ACTIVE_LOW>;

		pinctrl-0 = <&eusb_b_reset_n>;
		pinctrl-names = "default";
	};

	/* EC @0x5b and @0x76 (ACPI I2C6); no Linux driver yet */
};

/*
 * ACPI: \_SB.I2C8 = QUP_0_SE_7 @ 0x00b9c000 = Linux i2c7. PS8833 retimer for
 * USB-C port 1 @0x08, same wiring as the Zenbook A14; probes and works.
 */
&i2c7 {
	clock-frequency = <400000>;

	status = "okay";

	/* Left-side user-adjacent port */
	typec-mux@8 {
		compatible = "parade,ps8833", "parade,ps8830";
		reg = <0x08>;

		clocks = <&rpmhcc RPMH_RF_CLK4>;

		vdd-supply = <&vreg_rtmr1_1p15>;
		vdd33-supply = <&vreg_rtmr1_3p3>;
		vdd33-cap-supply = <&vreg_rtmr1_3p3>;
		vddar-supply = <&vreg_rtmr1_1p15>;
		vddat-supply = <&vreg_rtmr1_1p15>;
		vddio-supply = <&vreg_rtmr1_1p8>;

		reset-gpios = <&tlmm 176 GPIO_ACTIVE_LOW>;

		pinctrl-0 = <&rtmr1_default>;
		pinctrl-names = "default";

		retimer-switch;
		orientation-switch;

		ports {
			#address-cells = <1>;
			#size-cells = <0>;

			port@0 {
				reg = <0>;

				retimer_ss1_ss_out: endpoint {
					remote-endpoint = <&pmic_glink_ss1_ss_in>;
				};
			};

			port@1 {
				reg = <1>;

				retimer_ss1_ss_in: endpoint {
					remote-endpoint = <&usb_1_ss1_qmpphy_out>;
				};
			};

			port@2 {
				reg = <2>;

				retimer_ss1_con_sbu_out: endpoint {
					remote-endpoint = <&pmic_glink_ss1_con_sbu_in>;
				};
			};
		};
	};
};

&i2c8 {
	/* ACPI: \_SB.I2C9 = QUP_1_SE_0 @ 0x00a80000 = Linux i2c8, 400 kHz */
	clock-frequency = <400000>;

	status = "okay";

	/*
	 * ACPI: \_SB.TSC1, _HID ELAN9008, _CID PNP0C50, slave 0x10,
	 * HID descriptor register 0x0001, GpioInt level-low shared.
	 * The ACPI GpioInt pin (0x0400) is a Windows PEP handle, not a TLMM
	 * number. Verified on hardware: tlmm 51 counts in /proc/interrupts on
	 * touch; the controller enumerates as ELAN 04F3:430A with multitouch
	 * and a stylus collection (MPP pen).
	 */
	touchscreen@10 {
		compatible = "hid-over-i2c";
		reg = <0x10>;

		hid-descr-addr = <0x1>;
		interrupts-extended = <&tlmm 51 IRQ_TYPE_LEVEL_LOW>;

		pinctrl-0 = <&ts0_default>;
		pinctrl-names = "default";

		wakeup-source;
	};
};

&lpass_tlmm {
	spkr_01_sd_n_active: spkr-01-sd-n-active-state {
		pins = "gpio12";
		function = "gpio";
		drive-strength = <16>;
		bias-disable;
		output-low;
	};
};

&lpass_vamacro {
	pinctrl-0 = <&dmic01_default>, <&dmic23_default>;
	pinctrl-names = "default";

	vdd-micb-supply = <&vreg_l1b_1p8>;
	qcom,dmic-sample-rate = <4800000>;
};

&mdss {
	status = "okay";
};

&mdss_dp0 {
	status = "okay";
};

&mdss_dp0_out {
	link-frequencies = /bits/ 64 <1620000000 2700000000 5400000000 8100000000>;
};

&mdss_dp1 {
	status = "okay";
};

&mdss_dp1_out {
	link-frequencies = /bits/ 64 <1620000000 2700000000 5400000000 8100000000>;
};

/* PZ13: no third USB-C/HDMI port, DP2 unused */
&mdss_dp2 {
	status = "disabled";
};

&mdss_dp3 {
	/delete-property/ #sound-dai-cells;

	pinctrl-0 = <&edp0_hpd_default>;
	pinctrl-names = "default";

	status = "okay";

	aux-bus {
		/*
		 * Samsung ATNA33AA08-0 OLED (EDID SDC 0x41b0). Dedicated driver
		 * with the panel's enable line, as on the Zenbook A14 and the
		 * Vivobook S15; the generic edp-panel driver does not know this
		 * panel and uses conservative timings (2 s before a power-on).
		 */
		panel: panel {
			compatible = "samsung,atna33aa08", "samsung,atna33xc20";
			enable-gpios = <&pmc8380_3_gpios 4 GPIO_ACTIVE_HIGH>;
			power-supply = <&vreg_edp_3p3>;

			pinctrl-0 = <&edp_bl_en>;
			pinctrl-names = "default";

			port {
				edp_panel_in: endpoint {
					remote-endpoint = <&mdss_dp3_out>;
				};
			};
		};
	};
};

&mdss_dp3_out {
	data-lanes = <0 1 2 3>;
	link-frequencies = /bits/ 64 <1620000000 2700000000 5400000000 8100000000>;

	remote-endpoint = <&edp_panel_in>;
};

&mdss_dp3_phy {
	vdda-phy-supply = <&vreg_l3j_0p8>;
	vdda-pll-supply = <&vreg_l2j_1p2>;

	status = "okay";
};

&pcie4 {
	pinctrl-0 = <&pcie4_default>;
	pinctrl-names = "default";

	status = "okay";
};

&pcie4_phy {
	/*
	 * Supplies match the Windows PEP votes (LDO3_I / LDO3_E). The QREF
	 * reference clock block additionally needs vreg_l3j_0p8, kept always-on
	 * above; without it the PHY init times out sporadically on battery.
	 */
	vdda-phy-supply = <&vreg_l3i_0p8>;
	vdda-pll-supply = <&vreg_l3e_1p2>;

	status = "okay";
};

&pcie4_port0 {
	reset-gpios = <&tlmm 146 GPIO_ACTIVE_LOW>;
	wake-gpios = <&tlmm 148 GPIO_ACTIVE_LOW>;
};

&pcie6a {
	vddpe-3v3-supply = <&vreg_nvme>;

	pinctrl-0 = <&pcie6a_default>;
	pinctrl-names = "default";

	status = "okay";
};

&pcie6a_phy {
	vdda-phy-supply = <&vreg_l1d_0p8>;
	vdda-pll-supply = <&vreg_l2j_1p2>;

	status = "okay";
};

&pcie6a_port0 {
	reset-gpios = <&tlmm 152 GPIO_ACTIVE_LOW>;
	wake-gpios = <&tlmm 154 GPIO_ACTIVE_LOW>;
};

&pm8550_gpios {
	vol_up_n_default: vol-up-n-state {
		pins = "gpio6";
		function = "normal";
		power-source = <1>;
		bias-pull-up;
		input-enable;
	};

	vol_down_n_default: vol-down-n-state {
		pins = "gpio8";
		function = "normal";
		power-source = <1>;
		bias-pull-up;
		input-enable;
	};

	rtmr0_default: rtmr0-reset-n-active-state {
		pins = "gpio10";
		function = "normal";
		power-source = <1>;
		bias-disable;
		input-disable;
		output-enable;
	};

	usb0_3p3_reg_en: usb0-3p3-reg-en-state {
		pins = "gpio11";
		function = "normal";
		power-source = <1>;
		bias-disable;
		input-disable;
		output-enable;
	};
};

&pm8550ve_8_gpios {
	misc_3p3_reg_en: misc-3p3-reg-en-state {
		pins = "gpio6";
		function = "normal";
		power-source = <1>;
		bias-disable;
		input-disable;
		output-enable;
		drive-push-pull;
		qcom,drive-strength = <PMIC_GPIO_STRENGTH_LOW>;
	};
};

&pm8550ve_9_gpios {
	usb0_1p8_reg_en: usb0-1p8-reg-en-state {
		pins = "gpio8";
		function = "normal";
		power-source = <1>;
		bias-disable;
		input-disable;
		output-enable;
	};
};

&pmc8380_3_gpios {
	edp_bl_en: edp-bl-en-state {
		pins = "gpio4";
		function = "normal";
		power-source = <1>; /* 1.8 V */
		qcom,drive-strength = <PMIC_GPIO_STRENGTH_MED>;
		bias-pull-down;
		input-disable;
		output-enable;
	};
};

&pmc8380_5_gpios {
	usb0_pwr_1p15_reg_en: usb0-pwr-1p15-reg-en-state {
		pins = "gpio8";
		function = "normal";
		power-source = <1>;
		bias-disable;
		input-disable;
		output-enable;
	};
};

&qupv3_0 {
	status = "okay";
};

&qupv3_1 {
	status = "okay";
};

&qupv3_2 {
	status = "okay";
};

&smb2360_0 {
	status = "okay";
};

&smb2360_0_eusb2_repeater {
	vdd18-supply = <&vreg_l3d_1p8>;
	vdd3-supply = <&vreg_l2b_3p0>;
};

&smb2360_1 {
	status = "okay";
};

&smb2360_1_eusb2_repeater {
	vdd18-supply = <&vreg_l3d_1p8>;
	vdd3-supply = <&vreg_l14b_3p0>;
};

&swr0 {
	status = "okay";

	pinctrl-0 = <&wsa_swr_active>, <&spkr_01_sd_n_active>;
	pinctrl-names = "default";

	/* WSA8845, left speaker */
	left_spkr: speaker@0,0 {
		compatible = "sdw20217020400";
		reg = <0 0>;
		reset-gpios = <&lpass_tlmm 12 GPIO_ACTIVE_LOW>;
		#sound-dai-cells = <0>;
		sound-name-prefix = "SpkrLeft";
		vdd-1p8-supply = <&vreg_l15b_1p8>;
		vdd-io-supply = <&vreg_l12b_1p2>;
		qcom,port-mapping = <1 2 3 7 10 13>;
	};

	/* WSA8845, right speaker */
	right_spkr: speaker@0,1 {
		compatible = "sdw20217020400";
		reg = <0 1>;
		reset-gpios = <&lpass_tlmm 12 GPIO_ACTIVE_LOW>;
		#sound-dai-cells = <0>;
		sound-name-prefix = "SpkrRight";
		vdd-1p8-supply = <&vreg_l15b_1p8>;
		vdd-io-supply = <&vreg_l12b_1p2>;
		qcom,port-mapping = <4 5 6 7 11 13>;
	};
};

&tlmm {
	gpio-reserved-ranges = <44 4>,  /* SPI11, TZ Protected */
			       <65 1>,  /* EC reset (active high), see Abel Vesa's
					  hamoa/purwa EC-reset series */
			       <90 1>;	/* Unknown, TZ Protected */

	cam_ir_default: cam-ir-default-state {
		mclk-pins {
			pins = "gpio97";
			function = "cam_mclk";
			drive-strength = <16>;
			bias-disable;
		};

		reset-n-pins {
			pins = "gpio111";
			function = "gpio";
			drive-strength = <2>;
			bias-disable;
		};
	};

	cam_rear_default: cam-rear-default-state {
		mclk-pins {
			pins = "gpio96";
			function = "cam_mclk";
			drive-strength = <16>;
			bias-disable;
		};

		reset-n-pins {
			pins = "gpio109";
			function = "gpio";
			drive-strength = <2>;
			bias-disable;
		};
	};

	cam_rgb_default: cam-rgb-default-state {
		mclk-pins {
			pins = "gpio100";
			function = "cam_aon";
			drive-strength = <16>;
			bias-disable;
		};

		reset-n-pins {
			pins = "gpio237";
			function = "gpio";
			drive-strength = <2>;
			bias-disable;
		};
	};

	eusb_a_reset_n: eusb-a-reset-n-state {
		pins = "gpio6";
		function = "gpio";
		drive-strength = <2>;
		bias-disable;
	};

	eusb_b_reset_n: eusb-b-reset-n-state {
		pins = "gpio184";
		function = "gpio";
		drive-strength = <2>;
		bias-disable;
	};

	edp_reg_en: edp-reg-en-state {
		pins = "gpio70";
		function = "gpio";
		drive-strength = <16>;
		bias-disable;
	};

	hall_int_n_default: hall-int-n-state {
		pins = "gpio92";
		function = "gpio";
		bias-disable;
	};

	echid_default: echid-default-state {
		pins = "gpio67";
		function = "gpio";
		bias-pull-up;
	};

	nvme_reg_en: nvme-reg-en-state {
		pins = "gpio18";
		function = "gpio";
		drive-strength = <2>;
		bias-disable;
	};

	pcie4_default: pcie4-default-state {
		clkreq-n-pins {
			pins = "gpio147";
			function = "pcie4_clk";
			drive-strength = <2>;
			bias-pull-up;
		};

		perst-n-pins {
			pins = "gpio146";
			function = "gpio";
			drive-strength = <2>;
			bias-disable;
		};

		wake-n-pins {
			pins = "gpio148";
			function = "gpio";
			drive-strength = <2>;
			bias-pull-up;
		};
	};

	pcie6a_default: pcie6a-default-state {
		clkreq-n-pins {
			pins = "gpio153";
			function = "pcie6a_clk";
			drive-strength = <2>;
			bias-pull-up;
		};

		perst-n-pins {
			pins = "gpio152";
			function = "gpio";
			drive-strength = <2>;
			bias-disable;
		};

		wake-n-pins {
			pins = "gpio154";
			function = "gpio";
			drive-strength = <2>;
			bias-pull-up;
		};
	};

	rtmr1_default: rtmr1-reset-n-active-state {
		pins = "gpio176";
		function = "gpio";
		drive-strength = <2>;
		bias-disable;
	};

	ts0_default: ts0-default-state {
		pins = "gpio51";
		function = "gpio";
		bias-pull-up;
	};

	usb1_pwr_1p15_reg_en: usb1-pwr-1p15-reg-en-state {
		pins = "gpio188";
		function = "gpio";
		drive-strength = <2>;
		bias-disable;
	};

	usb1_pwr_1p8_reg_en: usb1-pwr-1p8-reg-en-state {
		pins = "gpio175";
		function = "gpio";
		drive-strength = <2>;
		bias-disable;
	};

	usb1_pwr_3p3_reg_en: usb1-pwr-3p3-reg-en-state {
		pins = "gpio186";
		function = "gpio";
		drive-strength = <2>;
		bias-disable;
	};

	wcn_bt_en: wcn-bt-en-state {
		pins = "gpio116";
		function = "gpio";
		drive-strength = <16>;
		bias-disable;
	};

	wcn_sw_en: wcn-sw-en-state {
		pins = "gpio214";
		function = "gpio";
		drive-strength = <2>;
		bias-disable;
	};

	wcn_wlan_en: wcn-wlan-en-state {
		pins = "gpio117";
		function = "gpio";
		drive-strength = <8>;
		bias-disable;
	};
};

&uart21 {
	compatible = "qcom,geni-debug-uart";

	status = "okay";
};

&usb_1_ss0_hsphy {
	vdd-supply = <&vreg_l3j_0p8>;
	vdda12-supply = <&vreg_l2j_1p2>;

	phys = <&smb2360_0_eusb2_repeater>;

	status = "okay";
};

&usb_1_ss0_qmpphy {
	vdda-phy-supply = <&vreg_l1j_0p9>;
	vdda-pll-supply = <&vreg_l2j_1p2>;

	status = "okay";
};

&usb_1_ss0 {
	dr_mode = "host";

	status = "okay";
};

&usb_1_ss0_dwc3_hs {
	remote-endpoint = <&pmic_glink_ss0_hs_in>;
};

&usb_1_ss0_qmpphy_out {
	remote-endpoint = <&retimer_ss0_ss_in>;
};

&usb_1_ss1_hsphy {
	vdd-supply = <&vreg_l3j_0p8>;
	vdda12-supply = <&vreg_l2j_1p2>;

	phys = <&smb2360_1_eusb2_repeater>;

	status = "okay";
};

&usb_1_ss1_qmpphy {
	vdda-phy-supply = <&vreg_l2d_0p9>;
	vdda-pll-supply = <&vreg_l2j_1p2>;

	status = "okay";
};

&usb_1_ss1 {
	dr_mode = "host";

	status = "okay";
};

&usb_1_ss1_dwc3_hs {
	remote-endpoint = <&pmic_glink_ss1_hs_in>;
};

&usb_1_ss1_qmpphy_out {
	remote-endpoint = <&retimer_ss1_ss_in>;
};

/* PZ13: no third USB-C port */
&usb_1_ss2_qmpphy {
	status = "disabled";
};

&usb_mp {
	/*
	 * PZ13: the keyboard cover's pogo connector (USB 2.0 only, "Z13 Soft
	 * Keyboard" 0b05:1b6e) enumerates on the second port (xhci 1-2, hsphy1);
	 * port 0 has no external connector. The SuperSpeed QMP PHYs have no link
	 * partner and their initialisation times out at random ("88e3000.phy: phy
	 * initialization timed-out"), which takes the whole controller down with
	 * it. Run the controller on the high-speed PHYs only.
	 */
	phys = <&usb_mp_hsphy0>, <&usb_mp_hsphy1>;
	phy-names = "usb2-0", "usb2-1";
	maximum-speed = "high-speed";

	/*
	 * No USB wakeup from this controller: the keyboard cover cannot wake the
	 * tablet at all (a held key only triggers the keyboard's firmware reset;
	 * the tablet is woken with the power button). With wakeup enabled dwc3
	 * keeps the port in U3 across suspend, the cover's reset leaves the port
	 * stuck in link state Resume
	 * ("Port resume timed out, port 1-2", "Cannot enable") and only a
	 * re-initialisation of the controller recovers it. Without wakeup the
	 * core is shut down at suspend and rebuilt at resume; the cover is
	 * reset-resumed as the same device and works again once it has received
	 * its backlight feature report (install/pz13-cover-usb-resume).
	 */
	/delete-property/ wakeup-source;

	status = "okay";
};

&usb_mp_hsphy0 {
	vdd-supply = <&vreg_l2e_0p8>;
	vdda12-supply = <&vreg_l3e_1p2>;

	phys = <&eusb_repeater_a>;

	status = "okay";
};

&usb_mp_hsphy1 {
	/* Port 1 (xhci "1-2") is the keyboard cover's pogo connector. */
	vdd-supply = <&vreg_l2e_0p8>;
	vdda12-supply = <&vreg_l3e_1p2>;

	phys = <&eusb_repeater_b>;

	status = "okay";
};

&usb_mp_qmpphy0 {
	status = "disabled";
};

&usb_mp_qmpphy1 {
	status = "disabled";
};
